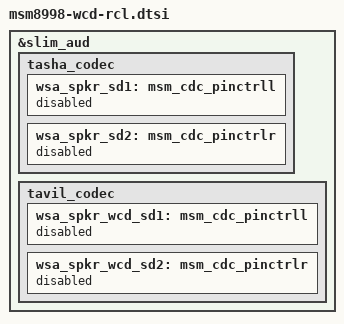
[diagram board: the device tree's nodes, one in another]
/* Copyright (c) 2016, The Linux Foundation. All rights reserved.
 *
 * This program is free software; you can redistribute it and/or modify
 * it under the terms of the GNU General Public License version 2 and
 * only version 2 as published by the Free Software Foundation.
 *
 * This program is distributed in the hope that it will be useful,
 * but WITHOUT ANY WARRANTY; without even the implied warranty of
 * MERCHANTABILITY or FITNESS FOR A PARTICULAR PURPOSE.  See the
 * GNU General Public License for more details.
 */

&slim_aud {
	tasha_codec {
		wsa_spkr_sd1: msm_cdc_pinctrll {
			/delete-property/ pinctrl-names;
			/delete-property/ pinctrl-0;
			/delete-property/ pinctrl-1;
			status = "disabled";
		};

		wsa_spkr_sd2: msm_cdc_pinctrlr {
			/delete-property/ pinctrl-names;
			/delete-property/ pinctrl-0;
			/delete-property/ pinctrl-1;
			status = "disabled";
		};
	};

	tavil_codec {
		wsa_spkr_wcd_sd1: msm_cdc_pinctrll {
			/delete-property/ pinctrl-names;
			/delete-property/ pinctrl-0;
			/delete-property/ pinctrl-1;
			status = "disabled";
		};

		wsa_spkr_wcd_sd2: msm_cdc_pinctrlr {
			/delete-property/ pinctrl-names;
			/delete-property/ pinctrl-0;
			/delete-property/ pinctrl-1;
			status = "disabled";
		};
	};
};
